# Cortex_M52 register map
Vendor: Arm Ltd.; Series: ARMv8.1-M Mainline; File version: 1.0.0
CPU: other r0p0, little endian, MPU, FPU, double-precision FPU, DSP, 8 interrupt priority bits
Registers are 32-bit, read-write, reset 0x0 unless marked. A register's access mark holds for its fields unless they carry their own. Offsets are from the block's base; [hi:lo] are bit positions; lines under a group give offsets from that group; {n}, {i} and the like mark numbered series; 'fields as' and 'values as' point back to an identical list.

## SCB — System Control Block: CPUID, exception control and state (ICSR, AIRCR, SHCSR), system configuration (SCR, CCR), system handler priorities, the fault status and address registers (CFSR, HFSR, DFSR, MMFAR, BFAR), CPU feature IDs, coprocessor access control, and on cores with caches the cache ID and maintenance registers.
Base 0xE000ED00
Same registers: SCB_NS 0xE002ED00
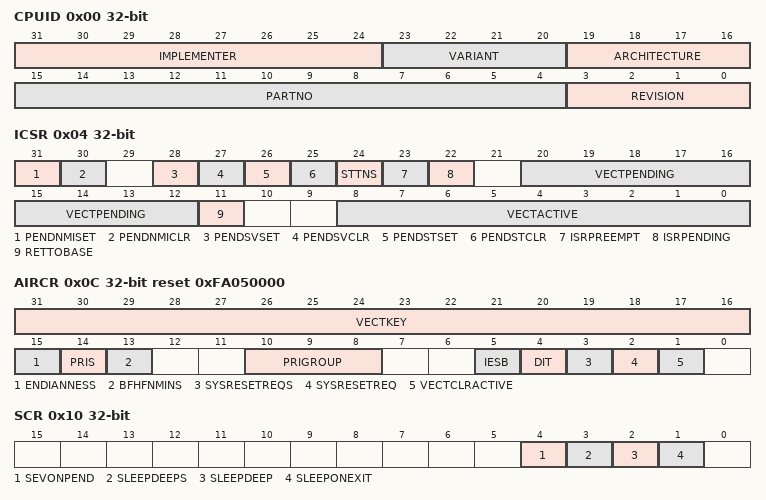
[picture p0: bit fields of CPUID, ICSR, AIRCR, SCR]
0x00 CPUID ro — CPUID Base Register: implementer, part number, architecture and revision of the processor (read-only).
  [31:24] IMPLEMENTER — Implementer code: 0x41 = Arm.
  [23:20] VARIANT — Major revision rN of the rNpM product revision.
  [19:16] ARCHITECTURE — Architecture: 0xC = ARMv6-M, 0xF = ARMv7-M or ARMv8-M (use ID_PFR/ID_ISAR for the details).
  [15:4] PARTNO — Part number: 0xC20 Cortex-M0, 0xC60 Cortex-M0+, 0xC21 Cortex-M1, 0xC23 Cortex-M3, 0xC24 Cortex-M4, 0xC27 Cortex-M7, 0xD20 Cortex-M23, 0xD21 Cortex-M33, 0xD31 Cortex-M35P, 0xD22 Cortex-M55, 0xD23 Cortex-M85, 0xD24 Cortex-M52.
  [3:0] REVISION — Minor revision pM of the rNpM product revision.
0x04 ICSR — Interrupt Control and State Register: active and pending exception numbers, and set/clear-pending controls for NMI, PendSV and SysTick.
  [31] PENDNMISET — Write 1 to set NMI pending; NMI is taken at once unless another NMI is active or the processor is halted. Reads 1 while pending. Secure or debugger access only when BFHFNMINS = 0.
  [30] PENDNMICLR wo — Write 1 to clear a pending NMI (ARMv8-M; Secure or debugger access only). Reads as 0.
  [28] PENDSVSET — Write 1 to set PendSV pending (the usual RTOS context-switch trigger); reads 1 while it is pending.
  [27] PENDSVCLR wo — Write 1 to clear a pending PendSV. Reads as 0.
  [26] PENDSTSET — Write 1 to set the SysTick exception pending; reads 1 while it is pending.
  [25] PENDSTCLR wo — Write 1 to clear a pending SysTick exception. Reads as 0.
  [24] STTNS — SysTick Targets Non-secure (Security Extension, single-SysTick implementations): 1 = the SysTick exception targets Non-secure state. Secure write only.
  [23] ISRPREEMPT ro — 1 = a pending exception will be serviced when the processor leaves Debug state (debug use only).
  [22] ISRPENDING ro — 1 = an external interrupt (IRQ, not NMI or a fault) is pending.
  [20:12] VECTPENDING ro — Exception number of the highest-priority pending enabled exception, 0 if none. Not affected by PRIMASK/FAULTMASK/BASEPRI.
  [11] RETTOBASE ro — 1 = the current handler is the only active exception (an exception return would go to Thread mode); 0 = another exception is preempted.
  [8:0] VECTACTIVE ro — Exception number of the currently executing handler; 0 in Thread mode. 2 NMI, 3 HardFault, 4 MemManage, 5 BusFault, 6 UsageFault, 7 SecureFault, 11 SVCall, 12 DebugMonitor, 14 PendSV, 15 SysTick, 16+n IRQn.
0x08 VTOR — Vector Table Offset Register: base address of the exception vector table. Must be aligned to the table size rounded up to a power of two (at least 128 bytes). Reset value is implementation defined (usually 0; set by SystemInit when the table is relocated).
  [31:7] TBLOFF — Vector table base address. The table must be aligned to its size rounded up to a power of two (at least 128 bytes; the low bits read as zero).
0x0C AIRCR reset 0xFA050000 — Application Interrupt and Reset Control Register: priority grouping, endianness, system reset request and (ARMv8-M) security attribution of BusFault/HardFault/NMI. Writes must place 0x05FA in VECTKEY or are ignored.
  [31:16] VECTKEY — Register key: writes must contain 0x05FA here or the whole write is ignored. Reads as 0xFA05 (VECTKEYSTAT).
  [15] ENDIANNESS ro — Data endianness: 0 = little-endian, 1 = big-endian (BE8). Read-only, sampled at reset.
    0=Little-endian data; 1=Big (Big-endian (BE8) data)
  [14] PRIS — Prioritize Secure exceptions (Security Extension): 1 = Non-secure exception priorities are mapped to the lower half of the range, so any Secure exception can preempt them.
  [13] BFHFNMINS — BusFault, HardFault and NMI Non-secure (Security Extension): 1 = these exceptions target Non-secure state and Secure faults escalate to the Non-secure HardFault. 0 = they target Secure state.
  [10:8] PRIGROUP — Priority grouping: bits [7:PRIGROUP+1] of each 8-bit priority are the group (preemption) priority, bits [PRIGROUP:0] the subpriority. 0 = 7 group bits (default), 7 = no preemption between interrupts (all subpriority).
    0=G7S1 (7 group priority bits [7:1], 1 subpriority bits [0:0]); 1=G6S2 (6 group priority bits [7:2], 2 subpriority bits [1:0]); 2=G5S3 (5 group priority bits [7:3], 3 subpriority bits [2:0]); 3=G4S4 (4 group priority bits [7:4], 4 subpriority bits [3:0]); 4=G3S5 (3 group priority bits [7:5], 5 subpriority bits [4:0]); 5=G2S6 (2 group priority bits [7:6], 6 subpriority bits [5:0]); 6=G1S7 (1 group priority bits [7:7], 7 subpriority bits [6:0]); 7=G0S8 (0 group priority bits [7:8], 8 subpriority bits [7:0])
  [5] IESB — Implicit Error Synchronization Barrier (ARMv8.1-M RAS): 1 = an error synchronization barrier is inserted on every exception entry and return.
  [4] DIT — Data Independent Timing (ARMv8.1-M): 1 = the execution time of data-processing instructions does not depend on the data values.
  [3] SYSRESETREQS — System reset request Secure only (Security Extension): 1 = only Secure software or the debugger can set SYSRESETREQ.
  [2] SYSRESETREQ — Write 1 (with VECTKEY = 0x05FA) to request a system reset (asserts SYSRESETREQ to the reset controller). Self-clearing; NVIC_SystemReset() uses this.
  [1] VECTCLRACTIVE — Debug use only: write 1 (with VECTKEY) to clear all active-exception state. Only while halted; otherwise unpredictable.
0x10 SCR — System Control Register: sleep-on-exit, deep sleep selection and send-event-on-pending.
  [4] SEVONPEND — Send Event on Pending: 1 = an interrupt becoming pending (even a disabled one) wakes the processor from WFE, enabling the WFE-polling idle pattern.
  [3] SLEEPDEEPS — Sleep Deep Secure only (Security Extension): 1 = SLEEPDEEP can only be written from Secure state.
  [2] SLEEPDEEP — 1 = WFI, WFE and sleep-on-exit request deep sleep (SLEEPDEEP output; the implementation-defined low-power mode, often stopping clocks/PLL) instead of sleep.
  [1] SLEEPONEXIT — 1 = the processor sleeps (as after WFI) whenever it returns from an exception handler to Thread mode. Interrupt-driven designs run entirely from handlers this way.
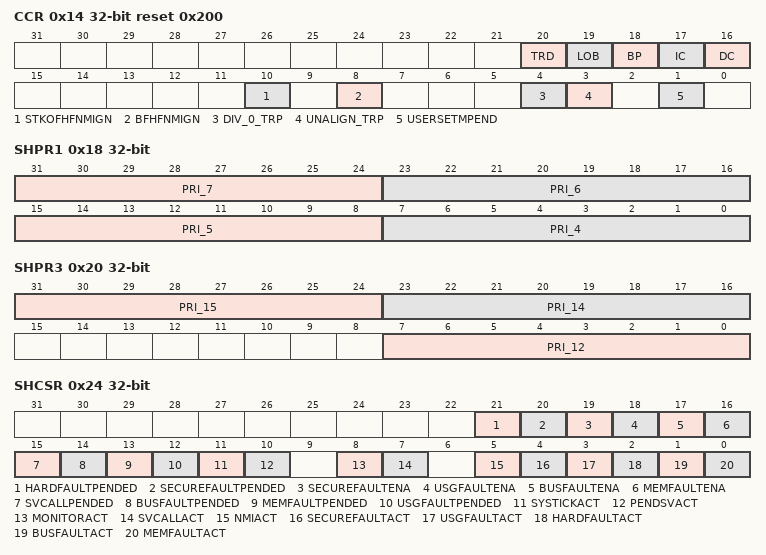
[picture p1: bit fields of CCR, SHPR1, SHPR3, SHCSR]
0x14 CCR reset 0x200 — Configuration and Control Register: trapping of divide-by-zero and unaligned accesses, stack alignment, unprivileged STIR access, Thread-mode return rules, and on cached cores the instruction/data cache and branch predictor enables.
  [20] TRD — Thread reentrancy disabled (ARMv8.1-M): 1 = an exception return to Thread mode while Thread mode is already active in the exception stack (re-entry) is faulted with INVPC; 0 = allowed.
  [19] LOB — Loop and branch info cache enable (ARMv8.1-M low-overhead-branch extension). Reset value 1 where implemented.
  [18] BP — Branch prediction enable. Reads as 1 (RAO) on Cortex-M7; on ARMv8-M cores it is implementation defined whether it is writable.
  [17] IC — Instruction cache enable. Invalidate before enabling (SCB_EnableICache).
  [16] DC — Data cache enable. Invalidate the cache before enabling (SCB_EnableDCache does this); clean before disabling.
  [10] STKOFHFNMIGN — Stack overflow ignored at priority -1/-2 (ARMv8-M): 1 = stack limit checks are disabled while executing at HardFault/NMI priority.
  [8] BFHFNMIGN — Bus faults ignored at priority -1/-2: 1 = precise data BusFaults are ignored (the load returns 0, the store is dropped) in HardFault, NMI and FAULTMASK handlers. Used by probing code that must not lock up.
  [4] DIV_0_TRP — 1 = SDIV/UDIV by zero raises a DIVBYZERO UsageFault; 0 = the result is 0.
  [3] UNALIGN_TRP — 1 = unaligned halfword/word loads and stores raise an UNALIGNED UsageFault. Multi-word accesses (LDM/STM/LDRD/STRD) always fault when unaligned. Always 1 on ARMv6-M.
  [1] USERSETMPEND — 1 = unprivileged software may write STIR to set interrupts pending.
0x18 SHPR1 — System Handler Priority Register 1: priorities of MemManage, BusFault, UsageFault and SecureFault. Only the top nvicPrioBits of each byte are implemented.
  [31:24] PRI_7 — Priority of system handler 7, SecureFault (Security Extension only).
  [23:16] PRI_6 — Priority of system handler 6, UsageFault.
  [15:8] PRI_5 — Priority of system handler 5, BusFault.
  [7:0] PRI_4 — Priority of system handler 4, MemManage.
0x1C SHPR2 — System Handler Priority Register 2: priority of SVCall. Only the top nvicPrioBits of each byte are implemented.
  [31:24] PRI_11 — Priority of system handler 11, SVCall.
0x20 SHPR3 — System Handler Priority Register 3: priorities of DebugMonitor, PendSV and SysTick. Only the top nvicPrioBits of each byte are implemented.
  [31:24] PRI_15 — Priority of system handler 15, SysTick.
  [23:16] PRI_14 — Priority of system handler 14, PendSV.
  [7:0] PRI_12 — Priority of system handler 12, DebugMonitor.
0x24 SHCSR — System Handler Control and State Register: enable bits for the configurable fault exceptions and the active/pending state of every system handler. A configurable fault whose enable bit is 0 escalates to HardFault.
  [21] HARDFAULTPENDED — HardFault pending (ARMv8-M).
  [20] SECUREFAULTPENDED — SecureFault pending.
  [19] SECUREFAULTENA — SecureFault exception enable: 0 = security violations escalate to (Secure) HardFault.
  [18] USGFAULTENA — UsageFault exception enable: 0 = undefined instructions, invalid state, NOCP, divide-by-zero etc. escalate to HardFault.
  [17] BUSFAULTENA — BusFault exception enable: 0 = bus errors escalate to HardFault.
  [16] MEMFAULTENA — MemManage exception enable: 0 = an MPU fault escalates to HardFault (HFSR.FORCED).
  [15] SVCALLPENDED — SVCall pending.
  [14] BUSFAULTPENDED — BusFault pending.
  [13] MEMFAULTPENDED — MemManage pending.
  [12] USGFAULTPENDED — UsageFault pending (a higher-priority exception is running).
  [11] SYSTICKACT — SysTick exception active.
  [10] PENDSVACT — PendSV exception active.
  [8] MONITORACT — DebugMonitor exception active.
  [7] SVCALLACT — SVCall exception active.
  [5] NMIACT — NMI exception active (ARMv8-M).
  [4] SECUREFAULTACT — SecureFault exception active (Security Extension).
  [3] USGFAULTACT — UsageFault exception active.
  [2] HARDFAULTACT — HardFault exception active (ARMv8-M).
  [1] BUSFAULTACT — BusFault exception active.
  [0] MEMFAULTACT — MemManage exception active. Software may write the active bits to fix up exception state, but must usually leave them alone.
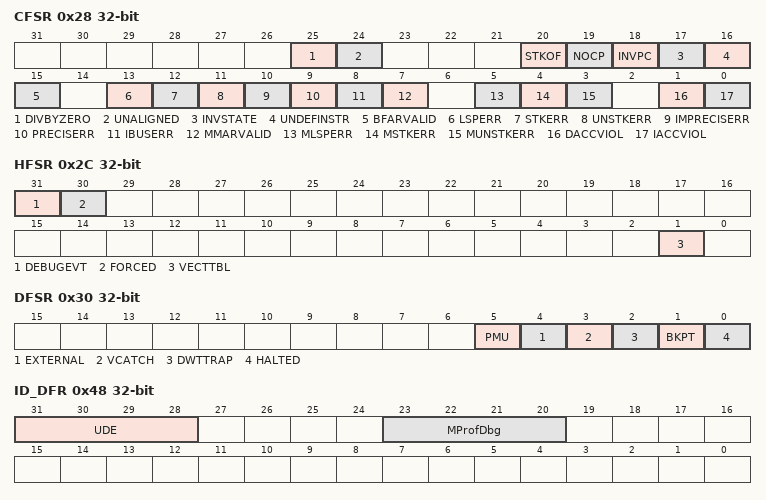
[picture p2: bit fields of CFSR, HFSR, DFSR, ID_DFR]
0x28 CFSR — Configurable Fault Status Register: MemManage (bits [7:0]), BusFault ([15:8]) and UsageFault ([31:16]) status. Bits are sticky and write-1-to-clear. With HFSR.FORCED set, this register holds the cause of the escalated HardFault.
  [25] DIVBYZERO — UsageFault: SDIV or UDIV by zero with CCR.DIV_0_TRP set.
  [24] UNALIGNED — UsageFault: unaligned access with CCR.UNALIGN_TRP set, or an unaligned multi-word access (LDM/STM/LDRD/STRD, exclusive or MVE vector access) which always faults.
  [20] STKOF — UsageFault: stack overflow - a push crossed the MSPLIM/PSPLIM stack limit (ARMv8-M).
  [19] NOCP — UsageFault: no coprocessor - an FPU/MVE or coprocessor instruction while the unit is disabled (SCB.CPACR CP10/CP11, NSACR, CPPWR) or absent. The usual cause of 'HardFault at first float operation'.
  [18] INVPC — UsageFault: invalid PC load on exception return - a corrupted EXC_RETURN in LR, or an exception return inconsistent with the active exception state.
  [17] INVSTATE — UsageFault: invalid EPSR state - almost always a branch to an address with bit 0 clear (Thumb bit not set), e.g. a null or corrupted function pointer, or a vector table entry without |1.
  [16] UNDEFINSTR — UsageFault: undefined instruction - an unknown opcode (corrupted code, wrong instruction set, an FP/DSP/MVE instruction the core lacks), or a coprocessor instruction on ARMv8-M without CDE.
  [15] BFARVALID — BFAR holds a valid fault address (precise faults only). Read BFAR before clearing this bit.
  [13] LSPERR — BusFault during lazy floating-point state preservation.
  [12] STKERR — BusFault while stacking on exception entry - the stack pointer points at unmapped memory (stack overflow past the end of RAM, uninitialised SP).
  [11] UNSTKERR — BusFault while unstacking on exception return (stack pointer corrupted or pointing at unmapped memory).
  [10] IMPRECISERR — Imprecise data BusFault: a buffered write failed after the instruction retired, so the stacked PC is somewhere after the faulting store and BFAR is not valid. Set ACTLR.DISDEFWBUF (Cortex-M3/M4) or add a DSB after suspect stores to make it precise.
  [9] PRECISERR — Precise data BusFault: the stacked PC is the faulting load/store and BFAR holds the address (when BFARVALID).
  [8] IBUSERR — BusFault on an instruction prefetch - executing from unmapped or faulting memory (corrupted PC/LR, wrong VTOR, jump through a bad function pointer).
  [7] MMARVALID — MMFAR holds a valid fault address. Read MMFAR before clearing this bit.
  [5] MLSPERR — MemManage during lazy floating-point state preservation (the FP frame at FPCAR is in a forbidden region).
  [4] MSTKERR — MemManage while stacking on exception entry - typically a stack overflow into a region the MPU forbids (e.g. a guard region below a thread stack).
  [3] MUNSTKERR — MemManage while unstacking on exception return - the stack pointer or an MPU region was changed during the handler.
  [1] DACCVIOL — MemManage: data access to an address the MPU forbids. MMFAR holds the address when MMARVALID is set; the stacked PC is the faulting instruction.
  [0] IACCVIOL — MemManage: instruction fetch from an address the MPU forbids (XN region, no execute permission, or a privileged-only region in unprivileged mode). MMFAR is not written.
0x2C HFSR — HardFault Status Register: why a HardFault was taken - vector table read error, escalation of a configurable fault (see CFSR) or a debug event. Write 1 to clear.
  [31] DEBUGEVT — A debug event caused the HardFault - e.g. a BKPT instruction executed with no debugger attached and DEMCR.MON_EN clear, or a vector catch. See DFSR.
  [30] FORCED — Escalated fault: a MemManage, BusFault, UsageFault or SecureFault that was disabled (SHCSR) or of insufficient priority became a HardFault. CFSR/SFSR still hold the original cause.
  [1] VECTTBL — A bus error occurred reading the vector table during exception entry - VTOR points at unmapped memory, or the table is missing/corrupted.
0x30 DFSR — Debug Fault Status Register: which debug event occurred (halt, breakpoint, watchpoint, vector catch, external request). Sticky, write 1 to clear.
  [5] PMU — PMU counter overflow caused a debug event (ARMv8.1-M, DHCSR.C_PMOV).
  [4] EXTERNAL — External debug request (the EDBGRQ input, typically driven by the CTI).
  [3] VCATCH — A vector catch fired (one of the DEMCR.VC_* bits): the processor halted on entry to the matching exception.
  [2] DWTTRAP — A DWT watchpoint (data or address comparator) matched.
  [1] BKPT — Breakpoint: a BKPT instruction was executed or an FPB comparator matched.
  [0] HALTED — Halt requested by the debugger (DHCSR.C_HALT or C_STEP), a DebugMonitor step, or a PMU/EDBGRQ halt.
0x34 MMFAR — MemManage Fault Address Register: the data address that caused a MemManage fault, valid when CFSR.MMARVALID is set.
  [31:0] ADDRESS — Data address of the MemManage fault (valid when CFSR.MMARVALID = 1).
0x38 BFAR — BusFault Address Register: the data address of a precise BusFault, valid when CFSR.BFARVALID is set. Not updated for imprecise faults.
  [31:0] ADDRESS — Data address of the precise BusFault (valid when CFSR.BFARVALID = 1).
0x3C AFSR — Auxiliary Fault Status Register: implementation-defined fault status (Cortex-M7 reports AXI/TCM/AHBP errors here and in ABFSR). Write 1 to clear.
  [31:0] IMPDEF — Implementation-defined auxiliary fault flags; write 1 to clear.
{0x40+4i} ID_PFR{i} (i=0..1) ro — Processor Feature Register n: ID_PFR0 lists the supported instruction sets (Thumb, Thumb-2), ID_PFR1 the programmers model (M-profile, Security Extension). Read-only.
0x48 ID_DFR ro — Debug Feature Register: the debug model implemented (M-profile debug, Unprivileged Debug Extension). Read-only.
  [31:28] UDE — Unprivileged Debug Extension (ARMv8.1-M): 0x1 = implemented.
  [23:20] MProfDbg — M-profile debug model: 0x1 = M-profile debug v1 (ARMv7-M/v8.0-M), 0x2 = v2 (ARMv8.1-M).
0x4C ID_AFR ro — Auxiliary Feature Register: implementation-defined features. Read-only.
{0x50+4i} ID_MMFR{i} (i=0..3) ro — Memory Model Feature Register n: PMSA support, cache and TCM features, alignment and barrier support. Read-only.
{0x60+4i} ID_ISAR{i} (i=0..5) ro — Instruction Set Attribute Register n: which instruction classes are implemented (e.g. ID_ISAR5 for the SIMD/MVE and FP features on ARMv8.1-M). Read-only.
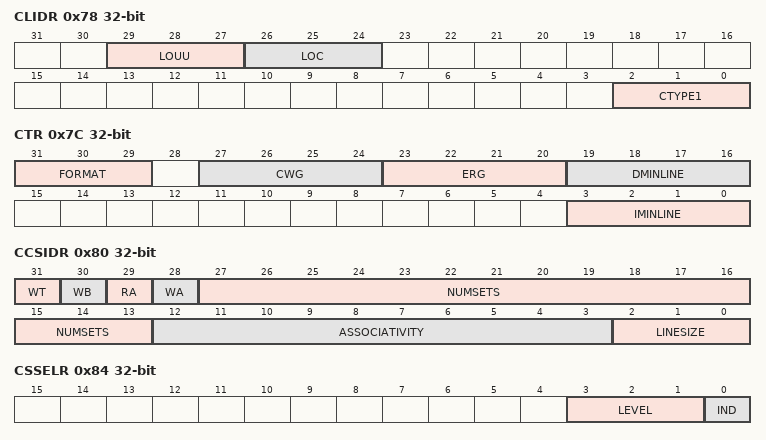
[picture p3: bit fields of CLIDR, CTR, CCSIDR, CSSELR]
0x78 CLIDR ro — Cache Level ID Register: which caches exist at each level and the levels of coherence and unification. Read-only.
  [29:27] LOUU — Level of Unification Uniprocessor: the number of cache levels to clean for instruction/data unification (1 = L1 only).
  [26:24] LOC — Level of Coherence: the number of cache levels to clean/invalidate for coherence with the point of coherency (1 = L1 only).
  [2:0] CTYPE1 — Cache type at level 1: 0 none, 1 instruction only, 2 data only, 3 separate instruction and data, 4 unified.
0x7C CTR ro — Cache Type Register: minimum instruction and data cache line sizes and the exclusives/write-back granules. Read-only.
  [31:29] FORMAT — Register format: 0b100 = ARMv7 CTR format.
  [27:24] CWG — Cache Writeback Granule: log2 words of the maximum size written back by a clean (0 = unknown).
  [23:20] ERG — Exclusives Reservation Granule: log2 words of the reservation granule of LDREX/STREX (0 = unknown).
  [19:16] DMINLINE — Log2 of the number of words in the smallest data cache line (3 = 32 bytes).
  [3:0] IMINLINE — Log2 of the number of words in the smallest instruction cache line (3 = 32 bytes on Cortex-M7/M55/M85).
0x80 CCSIDR ro — Cache Size ID Register: line size, associativity, number of sets and write policies of the cache selected by CSSELR. Read-only.
  [31] WT — Write-through supported.
  [30] WB — Write-back supported.
  [29] RA — Read-allocation supported.
  [28] WA — Write-allocation supported.
  [27:13] NUMSETS — Number of sets - 1. Cache size = (NUMSETS+1) x (ASSOCIATIVITY+1) x line size.
  [12:3] ASSOCIATIVITY — Associativity - 1 (number of ways - 1; Cortex-M7: 1 for the 2-way I-cache, 3 for the 4-way D-cache).
  [2:0] LINESIZE — Log2(words per cache line) - 2: 1 = 32-byte lines.
0x84 CSSELR — Cache Size Selection Register: selects which cache (level, instruction or data) CCSIDR describes.
  [3:1] LEVEL — Cache level - 1 (0 = level 1).
  [0] IND — Instruction not data: 0 = data or unified cache, 1 = instruction cache is described by CCSIDR.
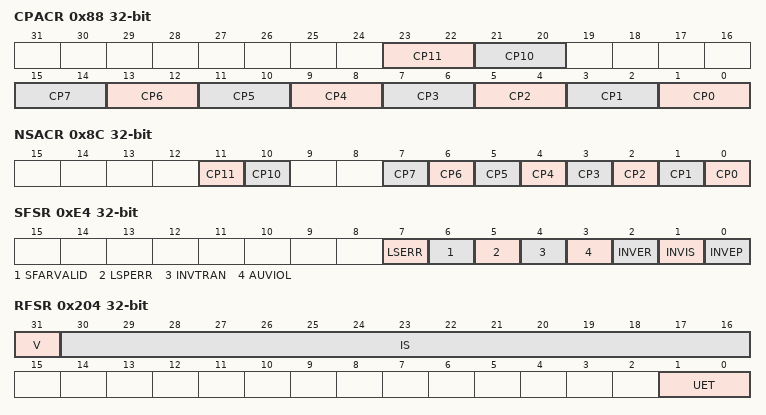
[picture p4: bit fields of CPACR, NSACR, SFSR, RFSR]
0x88 CPACR — Coprocessor Access Control Register: access rights for coprocessors 0-7 and for the FPU/MVE (CP10 and CP11, which must be set identically). An FP instruction with CP10/CP11 = 0 raises a NOCP UsageFault - the classic 'FPU not enabled' HardFault.
  [23:22] CP11 — FPU/MVE access (CP11): must be set identically to CP10.
  [21:20] CP10 — FPU/MVE access (CP10): 0 = denied - any FP instruction raises a NOCP UsageFault/HardFault, 1 = privileged only, 3 = full access. Must equal CP11.
  [2n+1:2n] CP{n} (n=0..7) — Access rights for coprocessor {n}: 0 = denied (NOCP UsageFault), 1 = privileged only, 3 = full access.
0x8C NSACR — Non-secure Access Control Register (Security Extension): which coprocessors Non-secure software may use. Secure access only.
  [11] CP11 — 1 = Non-secure software may use the FPU/MVE (CP11). Must equal CP10.
  [10] CP10 — 1 = Non-secure software may use the FPU/MVE (CP10). Must equal CP11.
  [n] CP{n} (n=0..7) — 1 = Non-secure software may use coprocessor {n} (custom datapath extension / CDE coprocessor).
0xE4 SFSR — SecureFault Status Register (Security Extension): why a SecureFault was taken. Sticky, write 1 to clear. Secure access only.
  [7] LSERR — Lazy state error: a Secure FP/MVE context could not be saved or restored across the security transition.
  [6] SFARVALID — SFAR holds a valid address (AUVIOL faults).
  [5] LSPERR — Error during lazy floating-point state preservation across security states.
  [4] INVTRAN — Invalid transition: a Secure-to-Non-secure branch not made with BXNS/BLXNS (for example calling a Non-secure function pointer directly, or a return to Non-secure code via a plain BX).
  [3] AUVIOL — Attribution unit violation: a Non-secure access to an address the SAU/IDAU marks Secure. SFAR holds the address when SFARVALID is set.
  [2] INVER — Invalid exception return: the EXC_RETURN or the exception stack does not match the security state (e.g. a Non-secure return from a Secure handler).
  [1] INVIS — Invalid integrity signature: the Secure exception frame being unstacked has a wrong integrity signature (stack corruption or wrong stack).
  [0] INVEP — Invalid entry point: a Non-secure branch into Secure code that did not land on an SG instruction in a Non-secure-callable region.
0xE8 SFAR — SecureFault Address Register: the address that caused an AUVIOL SecureFault, valid when SFSR.SFARVALID is set.
  [31:0] ADDRESS — Address of the SecureFault (valid when SFSR.SFARVALID = 1).
0x204 RFSR — RAS Fault Status Register (ARMv8.1-M RAS extension): records the most recent uncontained error. Write to clear.
  [31] V — Valid: 1 = a RAS error has been recorded in this register.
  [30:16] IS — Implementation-specific syndrome of the recorded error.
  [1:0] UET — Uncontainable error type: 0 = UC uncontainable, 1 = UEU unrecoverable, 2 = UEO restartable, 3 = UER recoverable.
0x250 ICIALLU wo — Instruction Cache Invalidate All to PoU: write any value to invalidate the whole instruction cache (and branch predictor). Write-only.
0x258 ICIMVAU wo — Instruction Cache Invalidate by address to PoU: write an address to invalidate the I-cache line containing it. Write-only.
  [31:0] ADDRESS — Any address inside the instruction cache line to invalidate.
0x25C DCIMVAC wo — Data Cache Invalidate by address to PoC: write an address to invalidate (discard) the D-cache line containing it. Write-only.
  [31:0] ADDRESS — Any address inside the data cache line to invalidate.
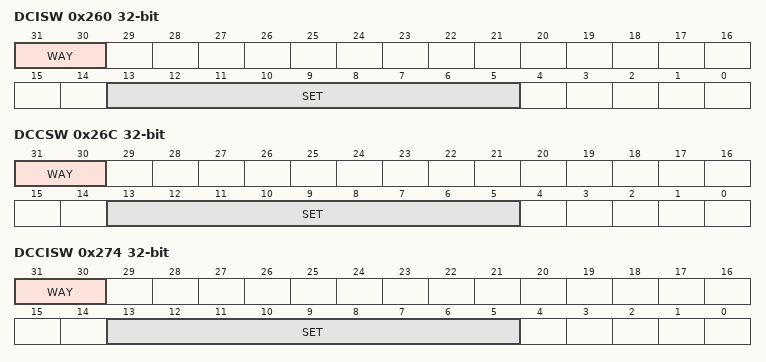
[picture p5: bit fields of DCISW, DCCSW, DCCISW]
0x260 DCISW wo — Data Cache Invalidate by Set/Way: write a set and way (see fields) to invalidate that line. Write-only.
  [31:30] WAY — Way of the cache line (0-3 on the 4-way Cortex-M7 data cache).
  [13:5] SET — Set index of the cache line (number of sets from CCSIDR).
0x264 DCCMVAU wo — Data Cache Clean by address to PoU: write an address to clean (write back) the line containing it to the point of unification. Write-only.
  [31:0] ADDRESS — Any address inside the data cache line to clean to the point of unification.
0x268 DCCMVAC wo — Data Cache Clean by address to PoC: write an address to clean (write back) the line containing it to the point of coherency. Write-only.
  [31:0] ADDRESS — Any address inside the data cache line to clean to the point of coherency.
0x26C DCCSW wo — Data Cache Clean by Set/Way: write a set and way to clean that line. Write-only.
  [31:30] WAY — Way of the cache line.
  [13:5] SET — Set index of the cache line.
0x270 DCCIMVAC wo — Data Cache Clean and Invalidate by address to PoC: write an address to write back and then invalidate its line. Write-only.
  [31:0] ADDRESS — Any address inside the data cache line to clean and invalidate.
0x274 DCCISW wo — Data Cache Clean and Invalidate by Set/Way. Write-only.
  fields as DCCSW
0x278 BPIALL wo — Branch Predictor Invalidate All: write any value to invalidate all branch predictor state. Write-only.
